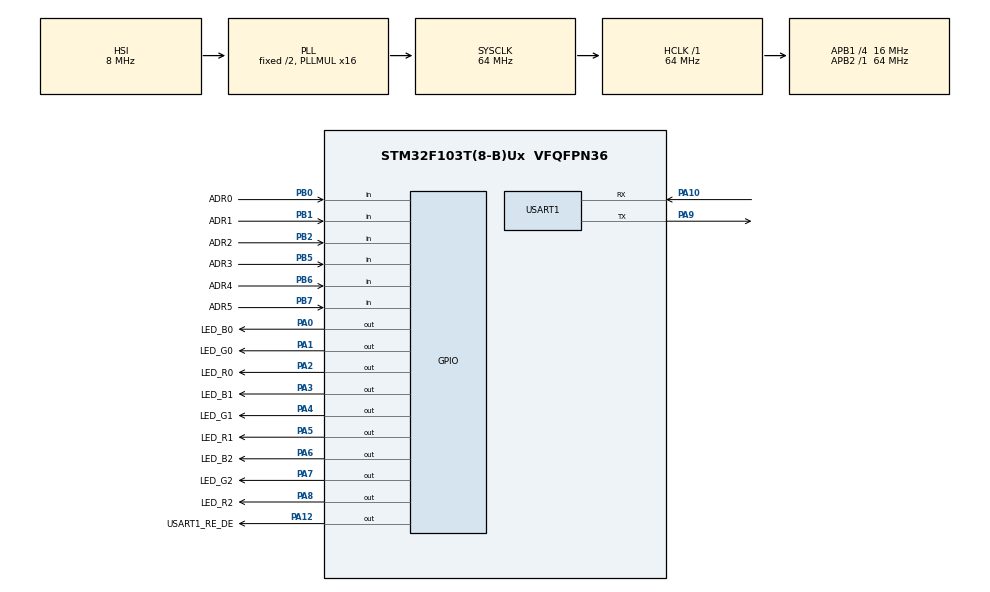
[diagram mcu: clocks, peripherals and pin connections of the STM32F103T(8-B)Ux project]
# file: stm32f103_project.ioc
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Mcu.Family=STM32F1
Mcu.Name=STM32F103T(8-B)Ux
Mcu.Package=VFQFPN36
NVIC.PriorityGroup=NVIC_PRIORITYGROUP_4
NVIC.TIM1_CC_IRQn=true\:0\:0\:false\:false\:true\:true
NVIC.TIM1_UP_IRQn=true\:0\:0\:false\:false\:true\:true
NVIC.USART1_IRQn=true\:0\:0\:false\:false\:true\:true
PA0-WKUP.GPIO_Label=LED_B0
PA0-WKUP.Signal=GPIO_Output
PA1.GPIO_Label=LED_G0
PA1.Signal=GPIO_Output
PA10.Mode=Asynchronous
PA10.Signal=USART1_RX
PA12.GPIO_Label=USART1_RE_DE
PA12.GPIO_Speed=GPIO_SPEED_FREQ_HIGH
PA12.Signal=GPIO_Output
PA2.GPIO_Label=LED_R0
PA2.Signal=GPIO_Output
PA3.GPIO_Label=LED_B1
PA3.Signal=GPIO_Output
PA4.GPIO_Label=LED_G1
PA4.Signal=GPIO_Output
PA5.GPIO_Label=LED_R1
PA5.Signal=GPIO_Output
PA6.GPIO_Label=LED_B2
PA6.Signal=GPIO_Output
PA7.GPIO_Label=LED_G2
PA7.Signal=GPIO_Output
PA8.GPIO_Label=LED_R2
PA8.Signal=GPIO_Output
PA9.Mode=Asynchronous
PA9.Signal=USART1_TX
PB0.GPIO_Label=ADR0
PB0.Signal=GPIO_Input
PB1.GPIO_Label=ADR1
PB1.Signal=GPIO_Input
PB2.GPIO_Label=ADR2
PB2.Signal=GPIO_Input
PB5.GPIO_Label=ADR3
PB5.Signal=GPIO_Input
PB6.GPIO_Label=ADR4
PB6.Signal=GPIO_Input
PB7.GPIO_Label=ADR5
PB7.Signal=GPIO_Input
ProjectManager.HeapSize=0x200
ProjectManager.StackSize=0x400
ProjectManager.TargetToolchain=SW4STM32
RCC.AHBFreq_Value=64000000
RCC.APB1CLKDivider=RCC_HCLK_DIV4
RCC.APB1Freq_Value=16000000
RCC.APB1TimFreq_Value=32000000
RCC.APB2Freq_Value=64000000
RCC.APB2TimFreq_Value=64000000
RCC.HCLKFreq_Value=64000000
RCC.PLLMUL=RCC_PLL_MUL16
RCC.SYSCLKFreq_VALUE=64000000
RCC.SYSCLKSource=RCC_SYSCLKSOURCE_PLLCLK
RCC.USBFreq_Value=64000000
TIM1.Channel-Output\ Compare1\ No\ Output=TIM_CHANNEL_1
TIM1.Period=65535
TIM1.Prescaler=63
TIM1.Pulse-Output\ Compare1\ No\ Output=365
USART1.VirtualMode=VM_ASYNC
VP_SYS_VS_ND.Mode=No_Debug
VP_TIM1_VS_ClockSourceINT.Mode=Internal
VP_TIM1_VS_no_output1.Mode=Output Compare1 No Output
board=custom

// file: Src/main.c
/**
  ******************************************************************************
  * @file           : main.c
  * @brief          : Main program body
  ******************************************************************************
  ** This notice applies to any and all portions of this file
  * that are not between comment pairs USER CODE BEGIN and
  * USER CODE END. Other portions of this file, whether
  * inserted by the user or by software development tools
  * are owned by their respective copyright owners.
  *
  * COPYRIGHT(c) 2018 STMicroelectronics
  *
  * Redistribution and use in source and binary forms, with or without modification,
  * are permitted provided that the following conditions are met:
  *   1. Redistributions of source code must retain the above copyright notice,
  *      this list of conditions and the following disclaimer.
  *   2. Redistributions in binary form must reproduce the above copyright notice,
  *      this list of conditions and the following disclaimer in the documentation
  *      and/or other materials provided with the distribution.
  *   3. Neither the name of STMicroelectronics nor the names of its contributors
  *      may be used to endorse or promote products derived from this software
  *      without specific prior written permission.
  *
  * THIS SOFTWARE IS PROVIDED BY THE COPYRIGHT HOLDERS AND CONTRIBUTORS "AS IS"
  * AND ANY EXPRESS OR IMPLIED WARRANTIES, INCLUDING, BUT NOT LIMITED TO, THE
  * IMPLIED WARRANTIES OF MERCHANTABILITY AND FITNESS FOR A PARTICULAR PURPOSE ARE
  * DISCLAIMED. IN NO EVENT SHALL THE COPYRIGHT HOLDER OR CONTRIBUTORS BE LIABLE
  * FOR ANY DIRECT, INDIRECT, INCIDENTAL, SPECIAL, EXEMPLARY, OR CONSEQUENTIAL
  * DAMAGES (INCLUDING, BUT NOT LIMITED TO, PROCUREMENT OF SUBSTITUTE GOODS OR
  * SERVICES; LOSS OF USE, DATA, OR PROFITS; OR BUSINESS INTERRUPTION) HOWEVER
  * CAUSED AND ON ANY THEORY OF LIABILITY, WHETHER IN CONTRACT, STRICT LIABILITY,
  * OR TORT (INCLUDING NEGLIGENCE OR OTHERWISE) ARISING IN ANY WAY OUT OF THE USE
  * OF THIS SOFTWARE, EVEN IF ADVISED OF THE POSSIBILITY OF SUCH DAMAGE.
  *
  ******************************************************************************
  */
#include "main.h"
#include "stm32f1xx_hal.h"
#include "tim.h"
#include "usart.h"
#include "gpio.h"

/* USER CODE BEGIN Includes */
#include "transfer.h"
#include "string.h"
#include "handlerModbus.h"
/* USER CODE END Includes */

/* USER CODE BEGIN PV */
/* Private variables ---------------------------------------------------------*/
// TEST UART_TX
extern uint8_t UnTxFlag;
// TEST UART_RX
extern uint8_t modbus_sm;
extern uint8_t UnIRQFlag;
extern uint8_t UnRxBuf[UN_BUF_SIZE]; // buffer for received data
extern uint16_t UnRxCnt;

/* USER CODE END PV */

void SystemClock_Config(void);

/* USER CODE BEGIN PFP */
/* Private function prototypes -----------------------------------------------*/

/* USER CODE END PFP */

int main(void)
{

  /* MCU Configuration----------------------------------------------------------*/

  /* Reset of all peripherals, Initializes the Flash interface and the Systick. */
  HAL_Init();

  /* Configure the system clock */
  SystemClock_Config();

  /* Initialize all configured peripherals */
  MX_GPIO_Init();
  MX_USART1_UART_Init();
  MX_TIM1_Init();

  /* Infinite loop */
  /* USER CODE BEGIN WHILE */

//TEST1
//  uint32_t curCnt;
//  uint8_t str[10];
//  HAL_TIM_OC_Start_IT(&htim1, TIM_CHANNEL_1);
//  while(1){
//    curCnt = __HAL_TIM_GET_COMPARE(&htim1, TIM_CHANNEL_1);
//    str[0]='N';
//    str[1]='0';
//    str[2]=(curCnt>>24)&0xFF;
//    str[3]=(curCnt>>16)&0xFF;
//    str[4]=(curCnt>>8)&0xFF;
//    str[5]=(curCnt)&0xFF;
//    str[6]='\n';
//    USARTN_RE_DE_TX;
//    HAL_UART_Transmit(&huart1, str, 7, 100);
//    USARTN_RE_DE_RX;
//    __HAL_TIM_SET_COMPARE(&htim1, TIM_CHANNEL_1, (uint32_t)(curCnt+365));
//    curCnt = __HAL_TIM_GET_COMPARE(&htim1, TIM_CHANNEL_1);
//    str[0]='N';
//    str[1]='1';
//    str[2]=(curCnt>>24)&0xFF;
//    str[3]=(curCnt>>16)&0xFF;
//    str[4]=(curCnt>>8)&0xFF;
//    str[5]=(curCnt)&0xFF;
//    str[6]='\n';
//    USARTN_RE_DE_TX;
//    HAL_UART_Transmit(&huart1, str, 7, 100);
//    USARTN_RE_DE_RX;
//    HAL_Delay(1000);
//  }

// TEST2
//  uint32_t tim1_cnt0, tim1_cnt1;
//  uint32_t tim1_border0=0, tim1_border1=2;
//
//  uint32_t i=0, j=0;
//  uint8_t buf_tx[16] = {'N','=','0','0','\n'};
//  HAL_TIM_Base_Start(&htim1);
//
//  j=__HAL_TIM_GET_AUTORELOAD(&htim1);
//  buf_tx[2] += (int)(j/10);
//  buf_tx[3] += j-buf_tx[2]+0x30;
//  USARTN_RE_DE_TX;
//  HAL_UART_Transmit(&huart1, buf_tx, 5, 1000);
//  USARTN_RE_DE_RX;
//
//  __HAL_TIM_SET_AUTORELOAD(&htim1, 50);
//  while(1){
//    //__HAL_TIM_SET_COUNTER(&htim1, tim1_cnt0+30);
//    tim1_cnt0 =__HAL_TIM_GET_COUNTER(&htim1);
//    if (tim1_cnt0==tim1_border0)
//        HAL_GPIO_WritePin(LED_G1_GPIO_Port, LED_G1_Pin, 1);
//    tim1_cnt0 =__HAL_TIM_GET_COUNTER(&htim1);
//    if (tim1_cnt0==tim1_border1)
//        HAL_GPIO_WritePin(LED_G1_GPIO_Port, LED_G1_Pin, 0);
//
//  }

// TEST 3 -- UART_TX
//  uint8_t *str="TEST01234\n";
//  uint8_t res;
//  while(1){
//    HAL_GPIO_WritePin(LED_G1_GPIO_Port, LED_G1_Pin, 1);
//    UnTxFlag = 1;
//    USARTN_RE_DE_TX;
//    HAL_GPIO_WritePin(LED_G1_GPIO_Port, LED_G1_Pin, 0);
//    HAL_UART_Transmit_IT(&huart1, str, 10);
//    while(UnTxFlag==1);
//    USARTN_RE_DE_RX;
//
//    HAL_Delay(1000);
//  }

 // TEST 3 -- UART_RX
//  uint8_t str[1];
//  uint8_t res;
//
//  receive_IT(str, 1);
//  modbus_sm =0;
//  while(1){
//    if(UnRxFlag){
//        receive_IT(str, 1);
//        UnRxFlag = 0;
//    }
//    if(modbus_sm){
//        HAL_GPIO_WritePin(LED_G1_GPIO_Port, LED_G1_Pin, 1);
//        abort_receiveIT();
//        modbus_sm = 0;
//        UnRxCnt = 0;
//        UnRxFlag = 1;
//        HAL_GPIO_WritePin(LED_G1_GPIO_Port, LED_G1_Pin, 0);
//    }
//  }

  // MAIN PROGRAM
  HAL_GPIO_WritePin(LED_G1_GPIO_Port, LED_G1_Pin, 0);
  // !!! TIM_Start -- >if use MARCOS in stm32f1xx_it.c !!!
  //HAL_TIM_Base_Start(&htim1);

  // MODBUS
  InitModbusDB();
  InitModbus();

  while (1)
  {

  /* USER CODE END WHILE */

  /* USER CODE BEGIN 3 */

/*  RS485-TRANSFER              */

    HandlerModbus();

    // !!! OLD CODE!!!!
    /*
    if(flag_tim1)
    {
        HAL_GPIO_TogglePin(LED_B1_GPIO_Port, LED_B1_Pin);

        abort_receiveIT();

        //copy rx_buffer
        u1tx_cnt = u1rx_cnt;
        u1rx_cnt = 0;
        memcpy(&u1tx_buf, &u1rx_buf, u1tx_cnt);
        memset(&u1rx_buf, 0xFF, u1tx_cnt);

        u1tx_flag = 1;
        u1tx_cnt_irq = u1tx_cnt;
        HAL_GPIO_WritePin(USART1_RE_DE_GPIO_Port, USART1_RE_DE_Pin, RS485_TX);

        receive_IT(u1tx_cnt);
        //HAL_UART_Receive_IT(&huart1, u1rx_buf_, u1tx_cnt);
        //transmit_IT(u1tx_buf, u1tx_cnt);
        HAL_UART_Transmit_DMA(&huart1, (uint8_t *)u1tx_buf, u1tx_cnt);
        while(u1tx_flag==1);
        HAL_Delay(100);
        HAL_GPIO_WritePin(USART1_RE_DE_GPIO_Port, USART1_RE_DE_Pin, RS485_RX);
        u1tx_flag = 0;

// test echo
        for(i=0;i<u1tx_cnt;i++){
            u1rx_buf[i]+=0x10; //+j
        }
        j++;

        HAL_GPIO_WritePin(USART1_RE_DE_GPIO_Port, USART1_RE_DE_Pin, RS485_TX);
        HAL_UART_Transmit(&huart1, u1rx_buf, u1rx_cnt, 1000);
        HAL_GPIO_WritePin(USART1_RE_DE_GPIO_Port, USART1_RE_DE_Pin, RS485_RX);
        res = __HAL_UART_GET_FLAG(&huart1, UART_FLAG_RXNE);
        while(res != 0){
        HAL_UART_Receive(&huart1, u1rx_buf, 1, 1000);
        res = __HAL_UART_GET_FLAG(&huart1, UART_FLAG_RXNE);
        }

        //clear rx_buffer and counter
        memset(&u1rx_buf, 0, u1tx_cnt);
        u1rx_cnt = 0;
        flag_tim1 =0;
        u1rx_flag = 1;

    }

    if(u1rx_flag)
    {
        receive_IT(1);
      //HAL_UART_Receive_IT(&huart1, u1rx_buf_, 1);
      u1rx_flag = 0;
    }
    */

  }

  /* USER CODE END 3 */

}

void SystemClock_Config(void)
{

  RCC_OscInitTypeDef RCC_OscInitStruct;
  RCC_ClkInitTypeDef RCC_ClkInitStruct;

    /**Initializes the CPU, AHB and APB busses clocks
    */
  RCC_OscInitStruct.OscillatorType = RCC_OSCILLATORTYPE_HSI;
  RCC_OscInitStruct.HSIState = RCC_HSI_ON;
  RCC_OscInitStruct.HSICalibrationValue = 16;
  RCC_OscInitStruct.PLL.PLLState = RCC_PLL_ON;
  RCC_OscInitStruct.PLL.PLLSource = RCC_PLLSOURCE_HSI_DIV2;
  RCC_OscInitStruct.PLL.PLLMUL = RCC_PLL_MUL16;
  if (HAL_RCC_OscConfig(&RCC_OscInitStruct) != HAL_OK)
  {
    _Error_Handler(__FILE__, __LINE__);
  }

    /**Initializes the CPU, AHB and APB busses clocks
    */
  RCC_ClkInitStruct.ClockType = RCC_CLOCKTYPE_HCLK|RCC_CLOCKTYPE_SYSCLK
                              |RCC_CLOCKTYPE_PCLK1|RCC_CLOCKTYPE_PCLK2;
  RCC_ClkInitStruct.SYSCLKSource = RCC_SYSCLKSOURCE_PLLCLK;
  RCC_ClkInitStruct.AHBCLKDivider = RCC_SYSCLK_DIV1;
  RCC_ClkInitStruct.APB1CLKDivider = RCC_HCLK_DIV4;
  RCC_ClkInitStruct.APB2CLKDivider = RCC_HCLK_DIV1;

  if (HAL_RCC_ClockConfig(&RCC_ClkInitStruct, FLASH_LATENCY_2) != HAL_OK)
  {
    _Error_Handler(__FILE__, __LINE__);
  }

    /**Configure the Systick interrupt time
    */
  HAL_SYSTICK_Config(HAL_RCC_GetHCLKFreq()/1000);

    /**Configure the Systick
    */
  HAL_SYSTICK_CLKSourceConfig(SYSTICK_CLKSOURCE_HCLK);

  /* SysTick_IRQn interrupt configuration */
  HAL_NVIC_SetPriority(SysTick_IRQn, 0, 0);
}

void _Error_Handler(char *file, int line)
{
  while(1)
  {
  }
}

/************************ (C) COPYRIGHT STMicroelectronics *****END OF FILE****/
